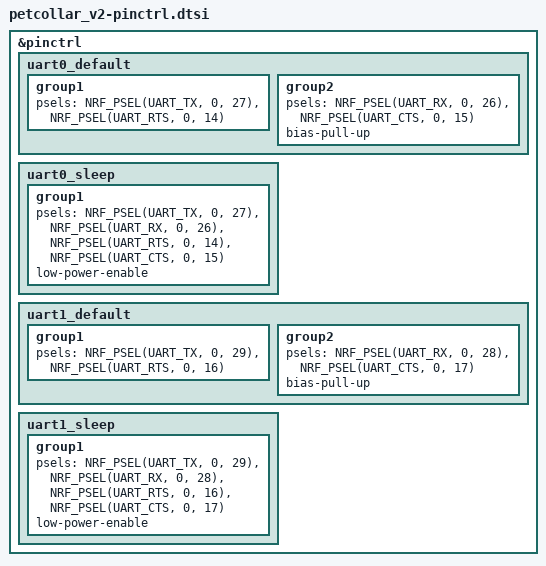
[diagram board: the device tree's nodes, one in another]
&pinctrl {
	uart0_default: uart0_default {
		group1 {
			psels = <NRF_PSEL(UART_TX, 0, 27)>,
				<NRF_PSEL(UART_RTS, 0, 14)>;
		};

		group2 {
			psels = <NRF_PSEL(UART_RX, 0, 26)>,
				<NRF_PSEL(UART_CTS, 0, 15)>;
			bias-pull-up;
		};
	};

	uart0_sleep: uart0_sleep {
		group1 {
			psels = <NRF_PSEL(UART_TX, 0, 27)>,
				<NRF_PSEL(UART_RX, 0, 26)>,
				<NRF_PSEL(UART_RTS, 0, 14)>,
				<NRF_PSEL(UART_CTS, 0, 15)>;
			low-power-enable;
		};
	};

    uart1_default: uart1_default {
		group1 {
			psels = <NRF_PSEL(UART_TX, 0, 29)>,
				<NRF_PSEL(UART_RTS, 0, 16)>;
		};

		group2 {
			psels = <NRF_PSEL(UART_RX, 0, 28)>,
				<NRF_PSEL(UART_CTS, 0, 17)>;
			bias-pull-up;
		};
	};

	uart1_sleep: uart1_sleep {
		group1 {
			psels = <NRF_PSEL(UART_TX, 0, 29)>,
				<NRF_PSEL(UART_RX, 0, 28)>,
				<NRF_PSEL(UART_RTS, 0, 16)>,
				<NRF_PSEL(UART_CTS, 0, 17)>;
			low-power-enable;
		};
	};
};
